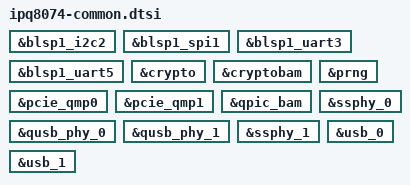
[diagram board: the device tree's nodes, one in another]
// SPDX-License-Identifier: GPL-2.0-or-later OR MIT

&blsp1_i2c2 {
	status = "okay";
};

&blsp1_spi1 {
	status = "okay";
};

&blsp1_uart3 {
	status = "okay";
};

&blsp1_uart5 {
	status = "okay";
};

&crypto {
	status = "okay";
};

&cryptobam {
	status = "okay";
};

&pcie_qmp0 {
	status = "okay";
};

&pcie_qmp1 {
	status = "okay";
};

&prng {
	status = "okay";
};

&qpic_bam {
	status = "okay";
};

&qusb_phy_0 {
	status = "okay";
};

&qusb_phy_1 {
	status = "okay";
};

&ssphy_0 {
	status = "okay";
};

&ssphy_1 {
	status = "okay";
};

&usb_0 {
	status = "okay";
};

&usb_1 {
	status = "okay";
};
